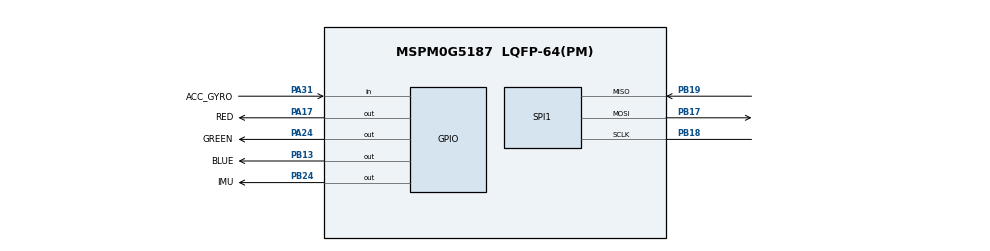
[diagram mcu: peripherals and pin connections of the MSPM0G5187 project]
//@cliArgs --device "MSPM0G518X" --package "LQFP-64(PM)" --part "Default"
//@v2CliArgs --device "MSPM0G5187" --package "LQFP-64(PM)"
// @cliArgs --board /ti/boards/LP_MSPM0G5187 --rtos nortos

/**
 * Import the modules used in this configuration.
 */
const GPIO          = scripting.addModule("/ti/driverlib/GPIO", {}, false);
const GPIO1         = GPIO.addInstance();
const GPIO2         = GPIO.addInstance();
const GPIO3         = GPIO.addInstance();
const SPI           = scripting.addModule("/ti/driverlib/SPI", {}, false);
const SPI1          = SPI.addInstance();
const SYSCTL        = scripting.addModule("/ti/driverlib/SYSCTL");
const ProjectConfig = scripting.addModule("/ti/project_config/ProjectConfig");

/**
 * Write custom configuration values to the imported modules.
 */
const divider7       = system.clockTree["PLL_PDIV"];
divider7.divideValue = 2;

const divider9       = system.clockTree["UDIV"];
divider9.divideValue = 2;

const multiplier2         = system.clockTree["PLL_QDIV"];
multiplier2.multiplyValue = 5;

const mux7       = system.clockTree["HSCLKMUX"];
mux7.inputSelect = "HSCLKMUX_SYSPLL2X";

GPIO1.$name                          = "CS";
GPIO1.associatedPins[0].$name        = "IMU";
GPIO1.associatedPins[0].initialValue = "SET";
GPIO1.associatedPins[0].pin.$assign  = "PB24";

const Board = scripting.addModule("/ti/driverlib/Board", {}, false);

GPIO2.$name                         = "SENSOR_INTR";
GPIO2.associatedPins[0].$name       = "ACC_GYRO";
GPIO2.associatedPins[0].direction   = "INPUT";
GPIO2.associatedPins[0].interruptEn = true;
GPIO2.associatedPins[0].polarity    = "RISE";
GPIO2.associatedPins[0].pin.$assign = "PA31";

GPIO3.$name                         = "GPIO_LED";
GPIO3.associatedPins.create(3);
GPIO3.associatedPins[0].$name       = "RED";
GPIO3.associatedPins[0].pin.$assign = "PA17";
GPIO3.associatedPins[1].$name       = "BLUE";
GPIO3.associatedPins[1].pin.$assign = "PB13";
GPIO3.associatedPins[2].$name       = "GREEN";
GPIO3.associatedPins[2].pin.$assign = "PA24";

SPI1.targetBitRate                      = 10000000;
SPI1.chipSelect                         = ["1","3"];
SPI1.frameFormat                        = "MOTO3";
SPI1.$name                              = "SPI";
SPI1.peripheral.$assign                 = "UC2";
SPI1.peripheral.sclkPin.$assign         = "PB18";
SPI1.peripheral.mosiPin.$assign         = "PB17";
SPI1.peripheral.misoPin.$assign         = "PB19";

SYSCTL.clockTreeEn = true;

ProjectConfig.genLibCMSIS = true;
